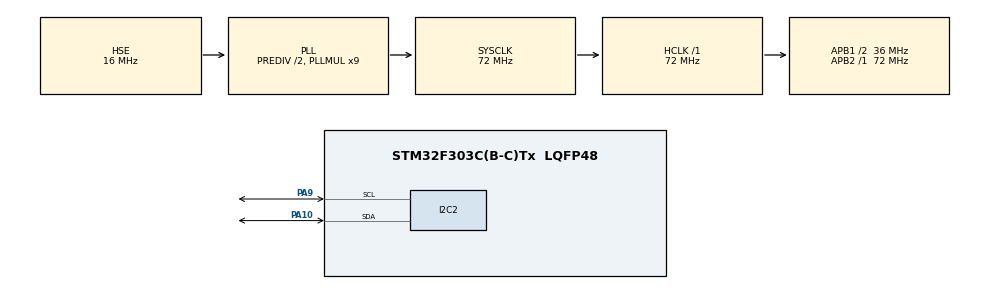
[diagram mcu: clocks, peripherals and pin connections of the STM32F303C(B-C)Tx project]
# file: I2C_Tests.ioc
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I2C2.I2C_Fall_Time=300
I2C2.I2C_Rise_Time=300
I2C2.Timing=0x00401E26
Mcu.Family=STM32F3
Mcu.Name=STM32F303C(B-C)Tx
Mcu.Package=LQFP48
NVIC.PriorityGroup=NVIC_PRIORITYGROUP_4
PA10.Mode=I2C
PA10.Signal=I2C2_SDA
PA13.Mode=Trace_Asynchronous_SW
PA13.Signal=SYS_JTMS-SWDIO
PA14.Mode=Trace_Asynchronous_SW
PA14.Signal=SYS_JTCK-SWCLK
PA9.Mode=I2C
PA9.Signal=I2C2_SCL
PB3.Mode=Trace_Asynchronous_SW
PB3.Signal=SYS_JTDO-TRACESWO
PF0-OSC_IN.Mode=HSE-External-Oscillator
PF0-OSC_IN.Signal=RCC_OSC_IN
PF1-OSC_OUT.Mode=HSE-External-Oscillator
PF1-OSC_OUT.Signal=RCC_OSC_OUT
ProjectManager.HeapSize=0x200
ProjectManager.StackSize=0x400
ProjectManager.TargetToolchain=TrueSTUDIO
RCC.AHBFreq_Value=72000000
RCC.APB1CLKDivider=RCC_HCLK_DIV2
RCC.APB1Freq_Value=36000000
RCC.APB1TimFreq_Value=72000000
RCC.APB2Freq_Value=72000000
RCC.APB2TimFreq_Value=72000000
RCC.CortexFreq_Value=72000000
RCC.HCLKFreq_Value=72000000
RCC.HSE_VALUE=16000000
RCC.HSI_VALUE=8000000
RCC.LSE_VALUE=32768
RCC.PLLMUL=RCC_PLL_MUL9
RCC.PLLSourceVirtual=RCC_PLLSOURCE_HSE
RCC.RCC_PLLsource_Clock_Source_FROM_HSE=RCC_HSE_PREDIV_DIV2
RCC.SYSCLKFreq_VALUE=72000000
RCC.SYSCLKSourceVirtual=RCC_SYSCLKSOURCE_PLLCLK
RCC.USBFreq_Value=72000000
board=I2C_Tests

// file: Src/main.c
/**
  ******************************************************************************
  * @file           : main.c
  * @brief          : Main program body
  ******************************************************************************
  ** This notice applies to any and all portions of this file
  * that are not between comment pairs USER CODE BEGIN and
  * USER CODE END. Other portions of this file, whether
  * inserted by the user or by software development tools
  * are owned by their respective copyright owners.
  *
  * COPYRIGHT(c) 2018 STMicroelectronics
  *
  * Redistribution and use in source and binary forms, with or without modification,
  * are permitted provided that the following conditions are met:
  *   1. Redistributions of source code must retain the above copyright notice,
  *      this list of conditions and the following disclaimer.
  *   2. Redistributions in binary form must reproduce the above copyright notice,
  *      this list of conditions and the following disclaimer in the documentation
  *      and/or other materials provided with the distribution.
  *   3. Neither the name of STMicroelectronics nor the names of its contributors
  *      may be used to endorse or promote products derived from this software
  *      without specific prior written permission.
  *
  * THIS SOFTWARE IS PROVIDED BY THE COPYRIGHT HOLDERS AND CONTRIBUTORS "AS IS"
  * AND ANY EXPRESS OR IMPLIED WARRANTIES, INCLUDING, BUT NOT LIMITED TO, THE
  * IMPLIED WARRANTIES OF MERCHANTABILITY AND FITNESS FOR A PARTICULAR PURPOSE ARE
  * DISCLAIMED. IN NO EVENT SHALL THE COPYRIGHT HOLDER OR CONTRIBUTORS BE LIABLE
  * FOR ANY DIRECT, INDIRECT, INCIDENTAL, SPECIAL, EXEMPLARY, OR CONSEQUENTIAL
  * DAMAGES (INCLUDING, BUT NOT LIMITED TO, PROCUREMENT OF SUBSTITUTE GOODS OR
  * SERVICES; LOSS OF USE, DATA, OR PROFITS; OR BUSINESS INTERRUPTION) HOWEVER
  * CAUSED AND ON ANY THEORY OF LIABILITY, WHETHER IN CONTRACT, STRICT LIABILITY,
  * OR TORT (INCLUDING NEGLIGENCE OR OTHERWISE) ARISING IN ANY WAY OUT OF THE USE
  * OF THIS SOFTWARE, EVEN IF ADVISED OF THE POSSIBILITY OF SUCH DAMAGE.
  *
  ******************************************************************************
  */
#include "main.h"
#include "stm32f3xx_hal.h"
#include "i2c.h"
#include "gpio.h"

/* USER CODE BEGIN Includes */
#include "drv_mpu6050.h"
#include "drv_mpu6050_hal.h"
#include "drv_mpu6050_reg.h"
/* USER CODE END Includes */

/* USER CODE BEGIN PV */
/* Private variables ---------------------------------------------------------*/
static drv_mpu6050_t      m_handler;
static drv_mpu6050_data_t m_data_acc;
static drv_mpu6050_data_t m_data_gyr;
/* USER CODE END PV */

void SystemClock_Config(void);

/* USER CODE BEGIN PFP */
/* Private function prototypes -----------------------------------------------*/

/* USER CODE END PFP */

int main(void)
{

  /* MCU Configuration----------------------------------------------------------*/

  /* Reset of all peripherals, Initializes the Flash interface and the Systick. */
  HAL_Init();

  /* Configure the system clock */
  SystemClock_Config();

  /* Initialize all configured peripherals */
  MX_GPIO_Init();
  MX_I2C2_Init();
  /* USER CODE BEGIN 2 */
  drv_mpu6050_init(&m_handler, drv_mpu6050_device_0);
  drv_mpu6050_set_acc(&m_handler, &m_data, drv_mpu6050_accelerometer_8g);
  drv_mpu6050_set_digital_lp_filter(&m_handler, drv_mpu6050_bandwidth_94Hz);

  /* USER CODE END 2 */

  /* Infinite loop */
  /* USER CODE BEGIN WHILE */
  while (1)
  {
	  HAL_Delay(100);
	  drv_mpu6050_read_acc(&m_handler,&m_data);
  /* USER CODE END WHILE */

  }

}

void SystemClock_Config(void)
{

  RCC_OscInitTypeDef RCC_OscInitStruct;
  RCC_ClkInitTypeDef RCC_ClkInitStruct;
  RCC_PeriphCLKInitTypeDef PeriphClkInit;

    /**Initializes the CPU, AHB and APB busses clocks
    */
  RCC_OscInitStruct.OscillatorType = RCC_OSCILLATORTYPE_HSI|RCC_OSCILLATORTYPE_HSE;
  RCC_OscInitStruct.HSEState = RCC_HSE_ON;
  RCC_OscInitStruct.HSEPredivValue = RCC_HSE_PREDIV_DIV2;
  RCC_OscInitStruct.HSIState = RCC_HSI_ON;
  RCC_OscInitStruct.HSICalibrationValue = 16;
  RCC_OscInitStruct.PLL.PLLState = RCC_PLL_ON;
  RCC_OscInitStruct.PLL.PLLSource = RCC_PLLSOURCE_HSE;
  RCC_OscInitStruct.PLL.PLLMUL = RCC_PLL_MUL9;
  if (HAL_RCC_OscConfig(&RCC_OscInitStruct) != HAL_OK)
  {
    _Error_Handler(__FILE__, __LINE__);
  }

    /**Initializes the CPU, AHB and APB busses clocks
    */
  RCC_ClkInitStruct.ClockType = RCC_CLOCKTYPE_HCLK|RCC_CLOCKTYPE_SYSCLK
                              |RCC_CLOCKTYPE_PCLK1|RCC_CLOCKTYPE_PCLK2;
  RCC_ClkInitStruct.SYSCLKSource = RCC_SYSCLKSOURCE_PLLCLK;
  RCC_ClkInitStruct.AHBCLKDivider = RCC_SYSCLK_DIV1;
  RCC_ClkInitStruct.APB1CLKDivider = RCC_HCLK_DIV2;
  RCC_ClkInitStruct.APB2CLKDivider = RCC_HCLK_DIV1;

  if (HAL_RCC_ClockConfig(&RCC_ClkInitStruct, FLASH_LATENCY_2) != HAL_OK)
  {
    _Error_Handler(__FILE__, __LINE__);
  }

  PeriphClkInit.PeriphClockSelection = RCC_PERIPHCLK_I2C2;
  PeriphClkInit.I2c2ClockSelection = RCC_I2C2CLKSOURCE_HSI;
  if (HAL_RCCEx_PeriphCLKConfig(&PeriphClkInit) != HAL_OK)
  {
    _Error_Handler(__FILE__, __LINE__);
  }

    /**Configure the Systick interrupt time
    */
  HAL_SYSTICK_Config(HAL_RCC_GetHCLKFreq()/1000);

    /**Configure the Systick
    */
  HAL_SYSTICK_CLKSourceConfig(SYSTICK_CLKSOURCE_HCLK);

  /* SysTick_IRQn interrupt configuration */
  HAL_NVIC_SetPriority(SysTick_IRQn, 0, 0);
}

void _Error_Handler(char *file, int line)
{
  while(1)
  {
  }
}

/************************ (C) COPYRIGHT STMicroelectronics *****END OF FILE****/
